# ATSAM4CMS32C_1 device description
Architecture: CORTEX-M4; Family: SAM4; Series: SAM4CM
Registers are 32-bit, read-write, no defined reset value unless marked. A register's access mark holds for its fields unless they carry their own. Offsets are from the block's base; [hi:lo] are bit positions; {n}, {i} and the like mark numbered series.

## AES — Advanced Encryption Standard
Instances: AES 0x40000000
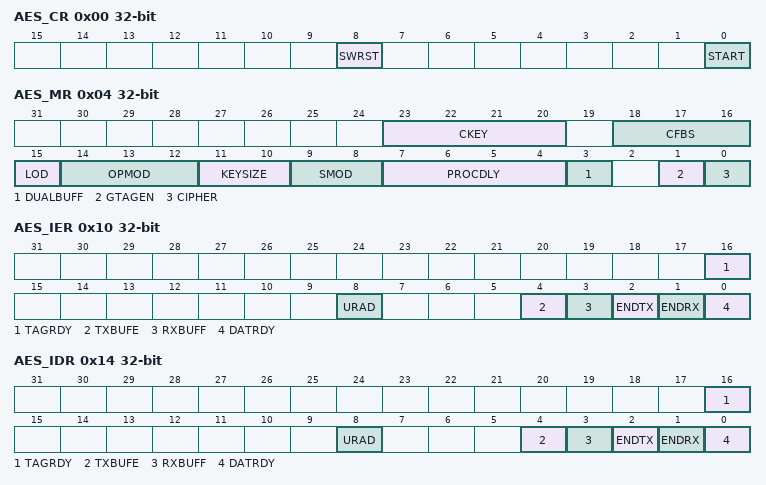
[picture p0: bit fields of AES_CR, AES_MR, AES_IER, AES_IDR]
0x00 AES_CR wo — Control Register
  [8] SWRST — Software Reset
  [0] START — Start Processing
0x04 AES_MR — Mode Register
  [23:20] CKEY — Key
    14=PASSWD (This field must be written with 0xE the first time that AES_MR is programmed. For subsequent programming of the AES_MR, any value can be written, including that of 0xE.Always reads as 0.)
  [18:16] CFBS — Cipher Feedback Data Size
    0=SIZE_128BIT (128-bit); 1=SIZE_64BIT (64-bit); 2=SIZE_32BIT (32-bit); 3=SIZE_16BIT (16-bit); 4=SIZE_8BIT (8-bit)
  [15] LOD — Last Output Data Mode
  [14:12] OPMOD — Operation Mode
    0=ECB (ECB: Electronic Code Book mode); 1=CBC (CBC: Cipher Block Chaining mode); 2=OFB (OFB: Output Feedback mode); 3=CFB (CFB: Cipher Feedback mode); 4=CTR (CTR: Counter mode (16-bit internal counter)); 5=GCM (GCM: Galois/Counter mode)
  [11:10] KEYSIZE
    0=AES128 (AES Key Size is 128 bits); 1=AES192 (AES Key Size is 192 bits); 2=AES256 (AES Key Size is 256 bits)
  [9:8] SMOD — Start Mode
    0=MANUAL_START (Manual Mode); 1=AUTO_START (Auto Mode); 2=IDATAR0_START (AES_IDATAR0 access only Auto Mode)
  [7:4] PROCDLY — Processing Delay
  [3] DUALBUFF — Dual Input Buffer
    0=INACTIVE (AES_IDATARx cannot be written during processing of previous block.); 1=ACTIVE (AES_IDATARx can be written during processing of previous block when SMOD = 0x2. It speeds up the overall runtime of large files.)
  [1] GTAGEN — GCM Automatic Tag Generation Enable
  [0] CIPHER — Processing Mode
0x10 AES_IER wo — Interrupt Enable Register
  [16] TAGRDY — GCM Tag Ready Interrupt Enable
  [8] URAD — Unspecified Register Access Detection Interrupt Enable
  [4] TXBUFE — Transmit Buffer Empty Interrupt Enable
  [3] RXBUFF — Receive Buffer Full Interrupt Enable
  [2] ENDTX — End of Transmit Buffer Interrupt Enable
  [1] ENDRX — End of Receive Buffer Interrupt Enable
  [0] DATRDY — Data Ready Interrupt Enable
0x14 AES_IDR wo — Interrupt Disable Register
  [16] TAGRDY — GCM Tag Ready Interrupt Disable
  [8] URAD — Unspecified Register Access Detection Interrupt Disable
  [4] TXBUFE — Transmit Buffer Empty Interrupt Disable
  [3] RXBUFF — Receive Buffer Full Interrupt Disable
  [2] ENDTX — End of Transmit Buffer Interrupt Disable
  [1] ENDRX — End of Receive Buffer Interrupt Disable
  [0] DATRDY — Data Ready Interrupt Disable
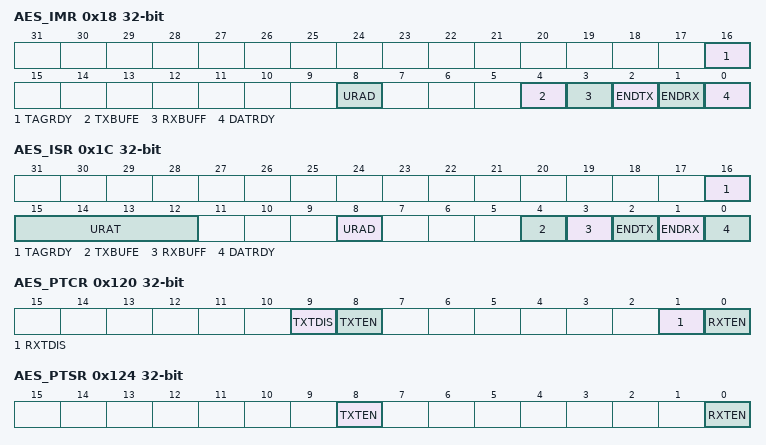
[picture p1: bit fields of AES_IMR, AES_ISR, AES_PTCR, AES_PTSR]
0x18 AES_IMR ro — Interrupt Mask Register
  [16] TAGRDY — GCM Tag Ready Interrupt Mask
  [8] URAD — Unspecified Register Access Detection Interrupt Mask
  [4] TXBUFE — Transmit Buffer Empty Interrupt Mask
  [3] RXBUFF — Receive Buffer Full Interrupt Mask
  [2] ENDTX — End of Transmit Buffer Interrupt Mask
  [1] ENDRX — End of Receive Buffer Interrupt Mask
  [0] DATRDY — Data Ready Interrupt Mask
0x1C AES_ISR ro — Interrupt Status Register
  [16] TAGRDY — GCM Tag Ready
  [15:12] URAT — Unspecified Register Access
    0=IDR_WR_PROCESSING (Input Data Register written during the data processing when SMOD = 0x2 mode.); 1=ODR_RD_PROCESSING (Output Data Register read during the data processing.); 2=MR_WR_PROCESSING (Mode Register written during the data processing.); 3=ODR_RD_SUBKGEN (Output Data Register read during the sub-keys generation.); 4=MR_WR_SUBKGEN (Mode Register written during the sub-keys generation.); 5=WOR_RD_ACCESS (Write-only register read access.)
  [8] URAD — Unspecified Register Access Detection Status
  [4] TXBUFE — TX Buffer Empty
  [3] RXBUFF — RX Buffer Full
  [2] ENDTX — End of TX Buffer
  [1] ENDRX — End of RX Buffer
  [0] DATRDY — Data Ready
{0x20+4i} AES_KEYWR{i} wo (i=0..7) — Key Word Register {i}
  [31:0] KEYW — Key Word
{0x40+4i} AES_IDATAR{i} wo (i=0..3) — Input Data Register {i}
  [31:0] IDATA — Input Data Word
{0x50+4i} AES_ODATAR{i} ro (i=0..3) — Output Data Register {i}
  [31:0] ODATA — Output Data
{0x60+4i} AES_IVR{i} wo (i=0..3) — Initialization Vector Register {i}
  [31:0] IV — Initialization Vector
0x70 AES_AADLENR — Additional Authenticated Data Length Register
  [31:0] AADLEN — Additional Authenticated Data Length
0x74 AES_CLENR — Plaintext/Ciphertext Length Register
  [31:0] CLEN — Plaintext/Ciphertext Length
{0x78+4i} AES_GHASHR{i} (i=0..3) — GCM Intermediate Hash Word Register {i}
  [31:0] GHASH — Intermediate GCM Hash Word x
{0x88+4i} AES_TAGR{i} ro (i=0..3) — GCM Authentication Tag Word Register {i}
  [31:0] TAG — GCM Authentication Tag x
0x98 AES_CTRR ro — GCM Encryption Counter Value Register
  [31:0] CTR — GCM Encryption Counter
{0x9C+4i} AES_GCMHR{i} (i=0..3) — GCM H Word Register {i}
  [31:0] H — GCM H Word x
0x100 AES_RPR — Receive Pointer Register
  [31:0] RXPTR
0x104 AES_RCR — Receive Counter Register
  [15:0] RXCTR
0x108 AES_TPR — Transmit Pointer Register
  [31:0] TXPTR — Transmit Counter Register
0x10C AES_TCR — Transmit Counter Register
  [15:0] TXCTR
0x110 AES_RNPR — Receive Next Pointer Register
  [31:0] RXNPTR — Receive Next Pointer
0x114 AES_RNCR — Receive Next Counter Register
  [15:0] RXNCTR — Receive Next Counter
0x118 AES_TNPR — Transmit Next Pointer Register
  [31:0] TXNPTR — Transmit Next Pointer
0x11C AES_TNCR — Transmit Next Counter Register
  [15:0] TXNCTR — Transmit Counter Next
0x120 AES_PTCR wo — Transfer Control Register
  [9] TXTDIS — Transmitter Transfer Disable
  [8] TXTEN — Transmitter Transfer Enable
  [1] RXTDIS — Receiver Transfer Disable
  [0] RXTEN — Receiver Transfer Enable
0x124 AES_PTSR ro — Transfer Status Register
  [8] TXTEN — Transmitter Transfer Enable
  [0] RXTEN — Receiver Transfer Enable

## Notices in the file
SAM Software Package License
Copyright (c) %copyright_year%, Atmel Corporation
All rights reserved.
Redistribution and use in source and binary forms, with or without
modification, are permitted provided that the following condition is met:
- Redistributions of source code must retain the above copyright notice,
this list of conditions and the disclaimer below.
Atmel's name may not be used to endorse or promote products derived from
this software without specific prior written permission.
DISCLAIMER:  THIS SOFTWARE IS PROVIDED BY ATMEL "AS IS" AND ANY EXPRESS OR
IMPLIED WARRANTIES, INCLUDING, BUT NOT LIMITED TO, THE IMPLIED WARRANTIES OF
MERCHANTABILITY, FITNESS FOR A PARTICULAR PURPOSE AND NON-INFRINGEMENT ARE
DISCLAIMED. IN NO EVENT SHALL ATMEL BE LIABLE FOR ANY DIRECT, INDIRECT,
INCIDENTAL, SPECIAL, EXEMPLARY, OR CONSEQUENTIAL DAMAGES (INCLUDING, BUT NOT
LIMITED TO, PROCUREMENT OF SUBSTITUTE GOODS OR SERVICES; LOSS OF USE, DATA,
OR PROFITS; OR BUSINESS INTERRUPTION) HOWEVER CAUSED AND ON ANY THEORY OF
LIABILITY, WHETHER IN CONTRACT, STRICT LIABILITY, OR TORT (INCLUDING
NEGLIGENCE OR OTHERWISE) ARISING IN ANY WAY OUT OF THE USE OF THIS SOFTWARE,
EVEN IF ADVISED OF THE POSSIBILITY OF SUCH DAMAGE.
